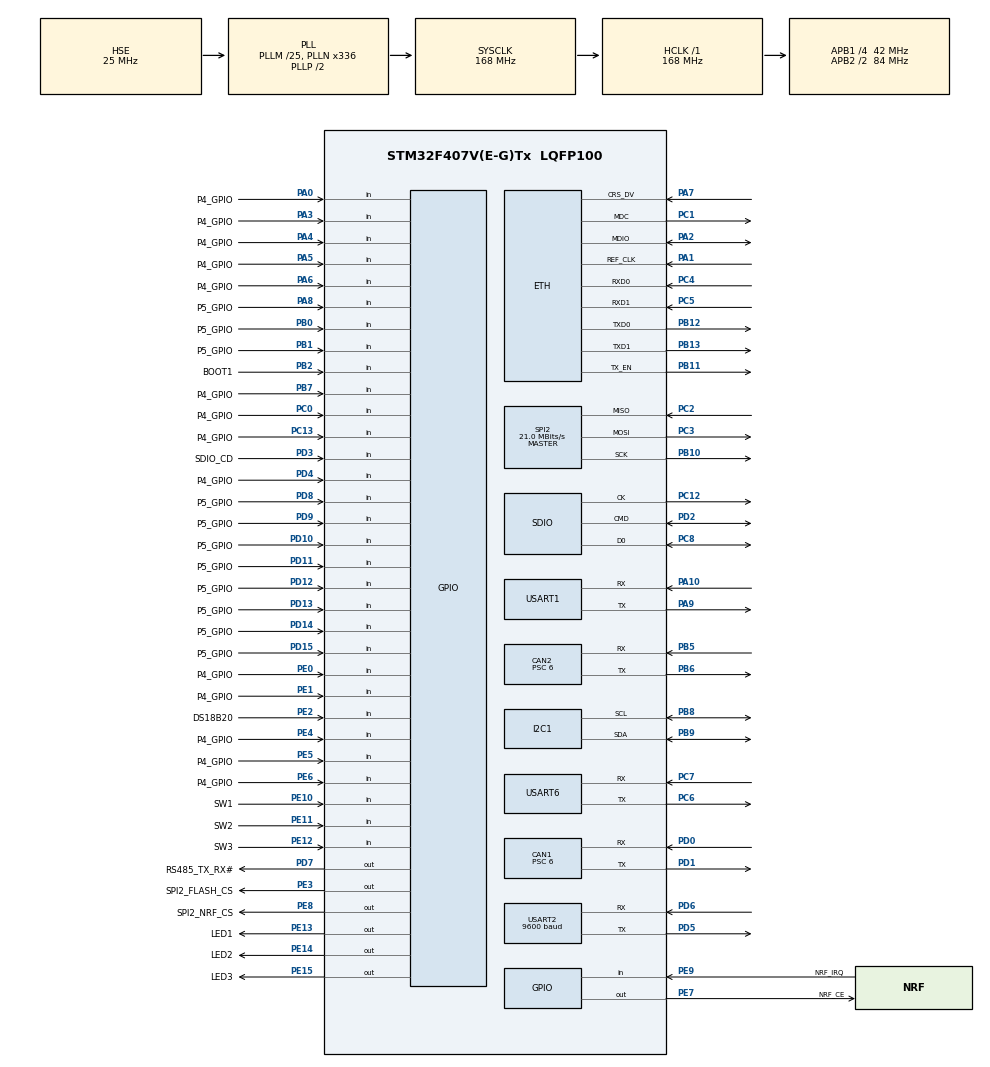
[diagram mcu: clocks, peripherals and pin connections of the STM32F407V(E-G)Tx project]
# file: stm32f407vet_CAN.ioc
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CAN1.BS1=CAN_BS1_6TQ
CAN1.BS2=CAN_BS2_7TQ
CAN1.CalculateBaudRate=500000
CAN1.CalculateTimeBit=2000
CAN1.CalculateTimeQuantum=142.85714285714286
CAN1.Prescaler=6
CAN2.BS1=CAN_BS1_6TQ
CAN2.BS2=CAN_BS2_7TQ
CAN2.CalculateBaudRate=500000
CAN2.CalculateTimeBit=2000
CAN2.CalculateTimeQuantum=142.85714285714286
CAN2.Prescaler=6
Dma.Request0=SDIO
Dma.SDIO.0.Direction=DMA_PERIPH_TO_MEMORY
Dma.SDIO.0.FIFOMode=DMA_FIFOMODE_ENABLE
Dma.SDIO.0.FIFOThreshold=DMA_FIFO_THRESHOLD_FULL
Dma.SDIO.0.Instance=DMA2_Stream3
Dma.SDIO.0.MemBurst=DMA_MBURST_INC4
Dma.SDIO.0.MemDataAlignment=DMA_MDATAALIGN_WORD
Dma.SDIO.0.MemInc=DMA_MINC_ENABLE
Dma.SDIO.0.Mode=DMA_PFCTRL
Dma.SDIO.0.PeriphBurst=DMA_PBURST_INC4
Dma.SDIO.0.PeriphDataAlignment=DMA_PDATAALIGN_WORD
Dma.SDIO.0.PeriphInc=DMA_PINC_DISABLE
Dma.SDIO.0.Priority=DMA_PRIORITY_LOW
ETH.MACAddr=00\:80\:E1\:00\:00\:AA
ETH.MediaInterface=HAL_ETH_RMII_MODE
FATFS.BSP.number=1
FATFS.USE_DMA_CODE_SD=1
FATFS0.BSP.STBoard=false
FATFS0.BSP.api=Unknown
FATFS0.BSP.instance=PD3
FATFS0.BSP.ip=GPIO
FATFS0.BSP.mode=Input
FATFS0.BSP.name=Detect_SDIO
FATFS0.BSP.solution=PD3
FREERTOS.Tasks01=defaultTask,0,512,StartDefaultTask,Default,NULL,Dynamic,NULL,NULL;myTask02,-2,256,StartTask02,Default,NULL,Dynamic,NULL,NULL;myTask03,-2,256,StartTask03,Default,NULL,Dynamic,NULL,NULL
FREERTOS.configUSE_NEWLIB_REENTRANT=1
LWIP.BSP.number=1
LWIP.CMSIS_VERSION-Enabled=1
LWIP.Version=v2.1.2_Cube
LWIP0.BSP.STBoard=false
LWIP0.BSP.api=BSP_COMPONENT_DRIVER
LWIP0.BSP.component=DP83848
LWIP0.BSP.instance=DP83848
LWIP0.BSP.name=Driver_PHY
LWIP0.BSP.semaphore=S_DP83848
LWIP0.BSP.solution=DP83848
Mcu.Family=STM32F4
Mcu.Name=STM32F407V(E-G)Tx
Mcu.Package=LQFP100
NVIC.CAN1_RX0_IRQn=true\:5\:0\:false\:false\:true\:true\:true\:true\:true
NVIC.CAN1_RX1_IRQn=true\:5\:0\:false\:false\:true\:true\:true\:true\:true
NVIC.CAN1_TX_IRQn=true\:5\:0\:false\:false\:true\:true\:true\:true\:true
NVIC.CAN2_RX0_IRQn=true\:5\:0\:false\:false\:true\:true\:true\:true\:true
NVIC.CAN2_RX1_IRQn=true\:5\:0\:false\:false\:true\:true\:true\:true\:true
NVIC.CAN2_TX_IRQn=true\:5\:0\:false\:false\:true\:true\:true\:true\:true
NVIC.DMA2_Stream3_IRQn=true\:5\:0\:false\:false\:true\:true\:false\:true\:true
NVIC.ETH_IRQn=true\:5\:0\:false\:false\:true\:true\:true\:true\:true
NVIC.PriorityGroup=NVIC_PRIORITYGROUP_4
NVIC.SDIO_IRQn=true\:5\:0\:false\:false\:true\:true\:true\:true\:true
NVIC.TIM6_DAC_IRQn=true\:15\:0\:false\:false\:true\:false\:false\:true\:true
NVIC.TimeBase=TIM6_DAC_IRQn
NVIC.TimeBaseIP=TIM6
NVIC.USART1_IRQn=true\:5\:0\:false\:false\:true\:true\:true\:true\:true
NVIC.USART2_IRQn=true\:5\:0\:false\:false\:true\:true\:true\:true\:true
PA0-WKUP.GPIO_Label=P4_GPIO
PA0-WKUP.Signal=GPIO_Input
PA1.Mode=RMII
PA1.Signal=ETH_REF_CLK
PA10.Mode=Asynchronous
PA10.Signal=USART1_RX
PA13.Mode=Serial_Wire
PA13.Signal=SYS_JTMS-SWDIO
PA14.Mode=Serial_Wire
PA14.Signal=SYS_JTCK-SWCLK
PA15.Signal=SYS_JTDI
PA2.Mode=RMII
PA2.Signal=ETH_MDIO
PA3.GPIO_Label=P4_GPIO
PA3.Signal=GPIO_Input
PA4.GPIO_Label=P4_GPIO
PA4.Signal=GPIO_Input
PA5.GPIO_Label=P4_GPIO
PA5.Signal=GPIO_Input
PA6.GPIO_Label=P4_GPIO
PA6.Signal=GPIO_Input
PA7.Mode=RMII
PA7.Signal=ETH_CRS_DV
PA8.GPIO_Label=P5_GPIO
PA8.Signal=GPIO_Input
PA9.Mode=Asynchronous
PA9.Signal=USART1_TX
PB0.GPIO_Label=P5_GPIO
PB0.Signal=GPIO_Input
PB1.GPIO_Label=P5_GPIO
PB1.Signal=GPIO_Input
PB10.Mode=Full_Duplex_Master
PB10.Signal=SPI2_SCK
PB11.Mode=RMII
PB11.Signal=ETH_TX_EN
PB12.Mode=RMII
PB12.Signal=ETH_TXD0
PB13.Mode=RMII
PB13.Signal=ETH_TXD1
PB2.GPIO_Label=BOOT1
PB2.Signal=GPIO_Input
PB3.Signal=SYS_JTDO-SWO
PB4.Signal=SYS_JTRST
PB5.Mode=CAN_Activate
PB5.Signal=CAN2_RX
PB6.Mode=CAN_Activate
PB6.Signal=CAN2_TX
PB7.GPIO_Label=P4_GPIO
PB7.Signal=GPIO_Input
PB8.Mode=I2C
PB8.Signal=I2C1_SCL
PB9.Mode=I2C
PB9.Signal=I2C1_SDA
PC0.GPIO_Label=P4_GPIO
PC0.Signal=GPIO_Input
PC1.Mode=RMII
PC1.Signal=ETH_MDC
PC12.Mode=SD_1_bit
PC12.Signal=SDIO_CK
PC13-ANTI_TAMP.GPIO_Label=P4_GPIO
PC13-ANTI_TAMP.Signal=GPIO_Input
PC2.Mode=Full_Duplex_Master
PC2.Signal=SPI2_MISO
PC3.Mode=Full_Duplex_Master
PC3.Signal=SPI2_MOSI
PC4.Mode=RMII
PC4.Signal=ETH_RXD0
PC5.Mode=RMII
PC5.Signal=ETH_RXD1
PC6.Mode=Asynchronous
PC6.Signal=USART6_TX
PC7.Mode=Asynchronous
PC7.Signal=USART6_RX
PC8.Mode=SD_1_bit
PC8.Signal=SDIO_D0
PD0.Mode=CAN_Activate
PD0.Signal=CAN1_RX
PD1.Mode=CAN_Activate
PD1.Signal=CAN1_TX
PD10.GPIO_Label=P5_GPIO
PD10.Signal=GPIO_Input
PD11.GPIO_Label=P5_GPIO
PD11.Signal=GPIO_Input
PD12.GPIO_Label=P5_GPIO
PD12.Signal=GPIO_Input
PD13.GPIO_Label=P5_GPIO
PD13.Signal=GPIO_Input
PD14.GPIO_Label=P5_GPIO
PD14.Signal=GPIO_Input
PD15.GPIO_Label=P5_GPIO
PD15.Signal=GPIO_Input
PD2.Mode=SD_1_bit
PD2.Signal=SDIO_CMD
PD3.GPIO_Label=SDIO_CD
PD3.Signal=GPIO_Input
PD4.GPIO_Label=P4_GPIO
PD4.Signal=GPIO_Input
PD5.Mode=Asynchronous
PD5.Signal=USART2_TX
PD6.Mode=Asynchronous
PD6.Signal=USART2_RX
PD7.GPIO_Label=RS485_TX_RX\#
PD7.Signal=GPIO_Output
PD8.GPIO_Label=P5_GPIO
PD8.Signal=GPIO_Input
PD9.GPIO_Label=P5_GPIO
PD9.Signal=GPIO_Input
PE0.GPIO_Label=P4_GPIO
PE0.Signal=GPIO_Input
PE1.GPIO_Label=P4_GPIO
PE1.Signal=GPIO_Input
PE10.GPIO_Label=SW1
PE10.Signal=GPIO_Input
PE11.GPIO_Label=SW2
PE11.Signal=GPIO_Input
PE12.GPIO_Label=SW3
PE12.Signal=GPIO_Input
PE13.GPIO_Label=LED1
PE13.PinState=GPIO_PIN_SET
PE13.Signal=GPIO_Output
PE14.GPIO_Label=LED2
PE14.PinState=GPIO_PIN_SET
PE14.Signal=GPIO_Output
PE15.GPIO_Label=LED3
PE15.PinState=GPIO_PIN_SET
PE15.Signal=GPIO_Output
PE2.GPIO_Label=DS18B20
PE2.Signal=GPIO_Input
PE3.GPIO_Label=SPI2_FLASH_CS
PE3.PinState=GPIO_PIN_SET
PE3.Signal=GPIO_Output
PE4.GPIO_Label=P4_GPIO
PE4.Signal=GPIO_Input
PE5.GPIO_Label=P4_GPIO
PE5.Signal=GPIO_Input
PE6.GPIO_Label=P4_GPIO
PE6.Signal=GPIO_Input
PE7.GPIO_Label=NRF_CE
PE7.Signal=GPIO_Output
PE8.GPIO_Label=SPI2_NRF_CS
PE8.PinState=GPIO_PIN_SET
PE8.Signal=GPIO_Output
PE9.GPIO_Label=NRF_IRQ
PE9.Signal=GPIO_Input
PH0-OSC_IN.Mode=HSE-External-Oscillator
PH0-OSC_IN.Signal=RCC_OSC_IN
PH1-OSC_OUT.Mode=HSE-External-Oscillator
PH1-OSC_OUT.Signal=RCC_OSC_OUT
ProjectManager.HeapSize=0x200
ProjectManager.StackSize=0x400
ProjectManager.TargetToolchain=STM32CubeIDE
RCC.48MHZClocksFreq_Value=48000000
RCC.AHBFreq_Value=168000000
RCC.APB1CLKDivider=RCC_HCLK_DIV4
RCC.APB1Freq_Value=42000000
RCC.APB1TimFreq_Value=84000000
RCC.APB2CLKDivider=RCC_HCLK_DIV2
RCC.APB2Freq_Value=84000000
RCC.APB2TimFreq_Value=168000000
RCC.CortexFreq_Value=168000000
RCC.HCLKFreq_Value=168000000
RCC.HSE_VALUE=25000000
RCC.HSI_VALUE=16000000
RCC.LSE_VALUE=32768
RCC.PLLM=25
RCC.PLLN=336
RCC.PLLQ=7
RCC.PLLSourceVirtual=RCC_PLLSOURCE_HSE
RCC.SYSCLKFreq_VALUE=168000000
RCC.SYSCLKSource=RCC_SYSCLKSOURCE_PLLCLK
RCC.VCOOutputFreq_Value=336000000
SDIO.ClockDiv=3
SDIO.ClockPowerSave=SDIO_CLOCK_POWER_SAVE_ENABLE
SDIO.HardwareFlowControl=SDIO_HARDWARE_FLOW_CONTROL_ENABLE
SPI2.CalculateBaudRate=21.0 MBits/s
SPI2.Direction=SPI_DIRECTION_2LINES
SPI2.Mode=SPI_MODE_MASTER
SPI2.VirtualType=VM_MASTER
USART1.VirtualMode=VM_ASYNC
USART2.BaudRate=9600
USART2.Parity=PARITY_ODD
USART2.VirtualMode=VM_ASYNC
USART6.VirtualMode=VM_ASYNC
VP_CRC_VS_CRC.Mode=CRC_Activate
VP_FATFS_VS_SDIO.Mode=SDIO
VP_FREERTOS_VS_CMSIS_V1.Mode=CMSIS_V1
VP_LWIP_VS_Enabled.Mode=Enabled
VP_RTC_VS_RTC_Activate.Mode=RTC_Enabled
VP_SYS_VS_tim6.Mode=TIM6
board=custom

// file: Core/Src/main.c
/* USER CODE BEGIN Header */
/**
  ******************************************************************************
  * @file           : main.c
  * @brief          : Main program body
  ******************************************************************************
  * @attention
  *
  * Copyright (c) 2024 STMicroelectronics.
  * All rights reserved.
  *
  * This software is licensed under terms that can be found in the LICENSE file
  * in the root directory of this software component.
  * If no LICENSE file comes with this software, it is provided AS-IS.
  *
  ******************************************************************************
  */
/* USER CODE END Header */
#include "main.h"
#include "cmsis_os.h"
#include "can.h"
#include "crc.h"
#include "dma.h"
#include "fatfs.h"
#include "i2c.h"
#include "lwip.h"
#include "rtc.h"
#include "sdio.h"
#include "spi.h"
#include "usart.h"
#include "gpio.h"

/* USER CODE BEGIN PD */
#ifdef __GNUC__
    #define PUTCHAR_PROTOTYPE int __io_putchar(int ch)
#else
    #define PUTCHAR_PROTOTYPE int fputc(int ch, FILE *f)
#endif

PUTCHAR_PROTOTYPE {
    HAL_UART_Transmit(&huart6, (uint8_t *)&ch, 1, HAL_MAX_DELAY);
    return ch;
}
/* USER CODE END PD */

void SystemClock_Config(void);
void MX_FREERTOS_Init(void);

int main(void)
{

  /* MCU Configuration--------------------------------------------------------*/

  /* Reset of all peripherals, Initializes the Flash interface and the Systick. */
  HAL_Init();

  /* Configure the system clock */
  SystemClock_Config();

  /* Initialize all configured peripherals */
  MX_GPIO_Init();
  MX_DMA_Init();
  MX_CAN1_Init();
  MX_CAN2_Init();
  MX_RTC_Init();
  MX_SDIO_SD_Init();
  MX_USART1_UART_Init();
  MX_USART2_UART_Init();
  MX_FATFS_Init();
  MX_CRC_Init();
  MX_SPI2_Init();
  MX_I2C1_Init();
  MX_USART6_UART_Init();

  /* Call init function for freertos objects (in cmsis_os2.c) */
  MX_FREERTOS_Init();

  /* Start scheduler */
  osKernelStart();

  /* We should never get here as control is now taken by the scheduler */

  /* Infinite loop */
  while (1)
  {

  }
}

void SystemClock_Config(void)
{
  RCC_OscInitTypeDef RCC_OscInitStruct = {0};
  RCC_ClkInitTypeDef RCC_ClkInitStruct = {0};

  /** Configure the main internal regulator output voltage
  */
  __HAL_RCC_PWR_CLK_ENABLE();
  __HAL_PWR_VOLTAGESCALING_CONFIG(PWR_REGULATOR_VOLTAGE_SCALE1);

  /** Initializes the RCC Oscillators according to the specified parameters
  * in the RCC_OscInitTypeDef structure.
  */
  RCC_OscInitStruct.OscillatorType = RCC_OSCILLATORTYPE_LSI|RCC_OSCILLATORTYPE_HSE;
  RCC_OscInitStruct.HSEState = RCC_HSE_ON;
  RCC_OscInitStruct.LSIState = RCC_LSI_ON;
  RCC_OscInitStruct.PLL.PLLState = RCC_PLL_ON;
  RCC_OscInitStruct.PLL.PLLSource = RCC_PLLSOURCE_HSE;
  RCC_OscInitStruct.PLL.PLLM = 25;
  RCC_OscInitStruct.PLL.PLLN = 336;
  RCC_OscInitStruct.PLL.PLLP = RCC_PLLP_DIV2;
  RCC_OscInitStruct.PLL.PLLQ = 7;
  if (HAL_RCC_OscConfig(&RCC_OscInitStruct) != HAL_OK)
  {
    Error_Handler();
  }

  /** Initializes the CPU, AHB and APB buses clocks
  */
  RCC_ClkInitStruct.ClockType = RCC_CLOCKTYPE_HCLK|RCC_CLOCKTYPE_SYSCLK
                              |RCC_CLOCKTYPE_PCLK1|RCC_CLOCKTYPE_PCLK2;
  RCC_ClkInitStruct.SYSCLKSource = RCC_SYSCLKSOURCE_PLLCLK;
  RCC_ClkInitStruct.AHBCLKDivider = RCC_SYSCLK_DIV1;
  RCC_ClkInitStruct.APB1CLKDivider = RCC_HCLK_DIV4;
  RCC_ClkInitStruct.APB2CLKDivider = RCC_HCLK_DIV2;

  if (HAL_RCC_ClockConfig(&RCC_ClkInitStruct, FLASH_LATENCY_5) != HAL_OK)
  {
    Error_Handler();
  }
}

void HAL_TIM_PeriodElapsedCallback(TIM_HandleTypeDef *htim)
{
  if (htim->Instance == TIM6) {
    HAL_IncTick();
  }
}

void Error_Handler(void)
{
  __disable_irq();
  while (1)
  {
  }
}

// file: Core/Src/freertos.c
/* USER CODE BEGIN Header */
/**
  ******************************************************************************
  * File Name          : freertos.c
  * Description        : Code for freertos applications
  ******************************************************************************
  * @attention
  *
  * Copyright (c) 2024 STMicroelectronics.
  * All rights reserved.
  *
  * This software is licensed under terms that can be found in the LICENSE file
  * in the root directory of this software component.
  * If no LICENSE file comes with this software, it is provided AS-IS.
  *
  ******************************************************************************
  */
/* USER CODE END Header */

#include "FreeRTOS.h"
#include "task.h"
#include "main.h"
#include "cmsis_os.h"

/* USER CODE BEGIN Includes */
#include "usart.h"
#include <stdio.h>
#include "lwip/api.h"
#include "lwip/sys.h"
#include "lwip/netdb.h"
#include "lwip/sockets.h"
#include "lwip/inet.h"
#include "string.h"
/* USER CODE END Includes */

/* USER CODE BEGIN PTD */
#define SERVER_IP   "192.168.55.146"  // Replace with your server's IP address
#define SERVER_PORT 6000             // Replace with your server's port
/* USER CODE END PTD */

/* USER CODE BEGIN PD */

extern CAN_HandleTypeDef hcan1;
extern CAN_HandleTypeDef hcan2	;
/* USER CODE END PD */

/* USER CODE BEGIN Variables */
osThreadId tcpClientTaskHandle;  //tcp client task handle
extern struct netif gnetif; //extern gnetif
/* USER CODE END Variables */
osThreadId defaultTaskHandle;
osThreadId myTask02Handle;
osThreadId myTask03Handle;

/* USER CODE BEGIN FunctionPrototypes */
void TcpClientTask(void const *argument){
	const char *server_ip = "192.168.0.27"; // Server IP
	const uint16_t server_port = 6000;       // Server Port
	char message[] = "Hello from STM32\r\n";
	//char recv_buffer[128];

	while (1) {
		// 1. Create a socket
		int sock = socket(AF_INET, SOCK_STREAM, IPPROTO_IP);
		if (sock < 0) {
			printf("Socket creation failed\n");
			vTaskDelay(pdMS_TO_TICKS(1000));
			continue;
		}

		// 2. Define server address
		struct sockaddr_in server_addr;
		server_addr.sin_family = AF_INET;
		server_addr.sin_port = htons(server_port);
		server_addr.sin_addr.s_addr = inet_addr(server_ip);

		// 3. Connect to the server
		if (connect(sock, (struct sockaddr *)&server_addr, sizeof(server_addr)) < 0) {
			printf("Connection failed\n");
			close(sock);
			vTaskDelay(pdMS_TO_TICKS(1000));
			continue;
		}

		// 4. Send data to the server
		if (send(sock, message, strlen(message), 0) < 0) {
			printf("Send failed\n");
			close(sock);
			vTaskDelay(pdMS_TO_TICKS(1000));
			continue;
		}

		// 5. Receive data from the server
//		int len = recv(sock, recv_buffer, sizeof(recv_buffer) - 1, 0);
//		if (len > 0) {
//			recv_buffer[len] = '\0';
//			printf("Received: %s\n", recv_buffer);
//		} else {
//			printf("Receive failed\n");
//		}

		// 6. Close the socket
		close(sock);

		// Delay before next connection attempt
		vTaskDelay(pdMS_TO_TICKS(5000));
	}
}
/* USER CODE END FunctionPrototypes */

void StartDefaultTask(void const * argument);
void StartTask02(void const * argument);
void StartTask03(void const * argument);

extern void MX_LWIP_Init(void);
void MX_FREERTOS_Init(void); /* (MISRA C 2004 rule 8.1) */

/* GetIdleTaskMemory prototype (linked to static allocation support) */
void vApplicationGetIdleTaskMemory( StaticTask_t **ppxIdleTaskTCBBuffer, StackType_t **ppxIdleTaskStackBuffer, uint32_t *pulIdleTaskStackSize );

/* USER CODE BEGIN GET_IDLE_TASK_MEMORY */
static StaticTask_t xIdleTaskTCBBuffer;
static StackType_t xIdleStack[configMINIMAL_STACK_SIZE];

void vApplicationGetIdleTaskMemory( StaticTask_t **ppxIdleTaskTCBBuffer, StackType_t **ppxIdleTaskStackBuffer, uint32_t *pulIdleTaskStackSize )
{
  *ppxIdleTaskTCBBuffer = &xIdleTaskTCBBuffer;
  *ppxIdleTaskStackBuffer = &xIdleStack[0];
  *pulIdleTaskStackSize = configMINIMAL_STACK_SIZE;
  /* place for user code */
}
/* USER CODE END GET_IDLE_TASK_MEMORY */

void MX_FREERTOS_Init(void) {

  /* Create the thread(s) */
  /* definition and creation of defaultTask */
  osThreadDef(defaultTask, StartDefaultTask, osPriorityNormal, 0, 512);
  defaultTaskHandle = osThreadCreate(osThread(defaultTask), NULL);

  /* definition and creation of myTask02 */
  osThreadDef(myTask02, StartTask02, osPriorityLow, 0, 256);
  myTask02Handle = osThreadCreate(osThread(myTask02), NULL);

  /* definition and creation of myTask03 */
  osThreadDef(myTask03, StartTask03, osPriorityLow, 0, 256);
  myTask03Handle = osThreadCreate(osThread(myTask03), NULL);

}

void StartDefaultTask(void const * argument)
{
  /* init code for LWIP */
  MX_LWIP_Init();
  /* USER CODE BEGIN StartDefaultTask */
  for(;;)
    {
  	  //Waiting for valid ip address
  	  if(gnetif.ip_addr.addr == 0 || gnetif.netmask.addr == 0 || gnetif.gw.addr == 0){
  		  osDelay(200);
  		  continue;
  	  }else{
  		  printf("\r\nDHCP/Static IP: %s\r\n", ip4addr_ntoa(netif_ip4_addr(&gnetif)));
  		  break;
  	  }
    }

    //Create the task to write to server

    //osDelay(5000);
    //TcpClientTask((void*)argument);
    //osThreadDef(tcpClientTask, StartTcpClientTask, osPriorityNormal, 0, 256);
    osThreadDef(tcpClientTask, TcpClientTask, osPriorityNormal, 0, 256);
    tcpClientTaskHandle = osThreadCreate(osThread(tcpClientTask), NULL); //run tcp client task

  //  osThreadDef(lwipWriteTask, WriteLWIPClientTask, osPriorityNormal, 0, 2048);
  //  lwipWriteTaskHandle = osThreadCreate(osThread(lwipWriteTask), NULL);

    //Create the task to read from server
  //  osThreadDef(lwipReadTask, ReadLWIPClientTask, osPriorityNormal, 0, 2048);
  //  lwipReadTaskHandle = osThreadCreate(osThread(lwipReadTask), NULL);

    /* Infinite loop */
    for(;;)
    {
  	//HAL_GPIO_TogglePin(LED_GREEN_GPIO_Port, LED_GREEN_Pin);
  	osDelay(500);
    }

  /* USER CODE END StartDefaultTask */
}

void StartTask02(void const * argument)
{
  /* USER CODE BEGIN StartTask02 */
	uint8_t tx_data[8] = {0};
	uint32_t tx_mailbox_number;

	// setup transmit header
	CAN_TxHeaderTypeDef tx_header;
	tx_header.StdId = 0x055;
	tx_header.RTR = CAN_RTR_DATA;
	tx_header.IDE = CAN_ID_STD;
	tx_header.DLC = 1U;
	tx_header.TransmitGlobalTime = DISABLE;

	  /* Infinite loop */
	  for(;;)
	  {
		  tx_data[0] = !tx_data[0];
		  HAL_CAN_AddTxMessage(&hcan1, &tx_header, tx_data, &tx_mailbox_number);

		  //printf("send %d\n", tx_data[0]);
		  //HAL_GPIO_TogglePin(LED3_GPIO_Port, LED3_Pin);
		  osDelay(1000);
	  }
  /* USER CODE END StartTask02 */
}

void StartTask03(void const * argument)
{
  /* USER CODE BEGIN StartTask03 */
  /* Infinite loop */

  for(;;)
  {
	  if (!HAL_GPIO_ReadPin(SW1_GPIO_Port, SW1_Pin)){
		  HAL_GPIO_TogglePin(LED1_GPIO_Port, LED1_Pin);
	  }

	  if (!HAL_GPIO_ReadPin(SW2_GPIO_Port, SW2_Pin)){
		  HAL_GPIO_TogglePin(LED2_GPIO_Port, LED2_Pin);
	  }
	  if (!HAL_GPIO_ReadPin(SW3_GPIO_Port, SW3_Pin)){
		  HAL_GPIO_TogglePin(LED3_GPIO_Port, LED3_Pin);
	  }
    osDelay(1);
  }
  /* USER CODE END StartTask03 */
}

/* USER CODE BEGIN Application */
// Callback for receiving messages via interrupt
void HAL_CAN_RxFifo0MsgPendingCallback(CAN_HandleTypeDef *CanHandle)
{

	CAN_RxHeaderTypeDef rx_header;
	uint8_t rx_data[8];

	HAL_CAN_GetRxMessage(CanHandle, CAN_RX_FIFO0, &rx_header, rx_data);

	HAL_GPIO_TogglePin(LED2_GPIO_Port, LED2_Pin);
//	if (rx_header.StdId == 0x34) {
//		HAL_GPIO_TogglePin(LED2_GPIO_Port, LED2_Pin);
//	}
//
//	if (rx_header.StdId == 0x43) {
//			HAL_GPIO_TogglePin(LED2_GPIO_Port, LED2_Pin);
//	}

}
void HAL_CAN_RxFifo1MsgPendingCallback(CAN_HandleTypeDef *CanHandle)
{

	CAN_RxHeaderTypeDef rx_header;
	uint8_t rx_data[8];

	HAL_CAN_GetRxMessage(CanHandle, CAN_RX_FIFO1, &rx_header, rx_data);

	if (rx_header.StdId == 0x34) {
		HAL_GPIO_TogglePin(LED3_GPIO_Port, LED3_Pin);
	}

	if (rx_header.StdId == 0x55) {
		//mprintf("recevied 0x55\n");
		HAL_GPIO_TogglePin(LED3_GPIO_Port, LED3_Pin);
	}

}
/* USER CODE END Application */
